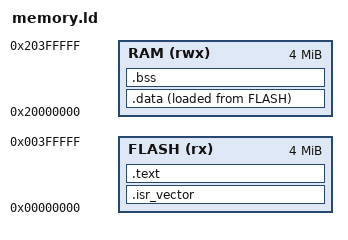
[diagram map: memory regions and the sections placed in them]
ENTRY(Reset_Handler)

MEMORY
{
    FLASH (rx)  : ORIGIN = 0x00000000, LENGTH = 4M
    RAM   (rwx) : ORIGIN = 0x20000000, LENGTH = 4M
}

__StackTop = ORIGIN(RAM) + LENGTH(RAM);

SECTIONS
{
    .isr_vector :
    {
        . = ALIGN(4);
        KEEP(*(.isr_vector))
        . = ALIGN(4);
    } > FLASH

    .text :
    {
        . = ALIGN(4);
        *(.text*)
        *(.rodata*)
        . = ALIGN(4);
    } > FLASH

    .data :
    {
        . = ALIGN(4);
        *(.data*)
        . = ALIGN(4);
    } > RAM AT > FLASH

    .bss (NOLOAD) :
    {
        . = ALIGN(4);
        *(.bss*)
        *(COMMON)
        . = ALIGN(4);
    } > RAM

    /DISCARD/ :
    {
        *(.comment)
        *(.note*)
        *(.eh_frame*)
    }
}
